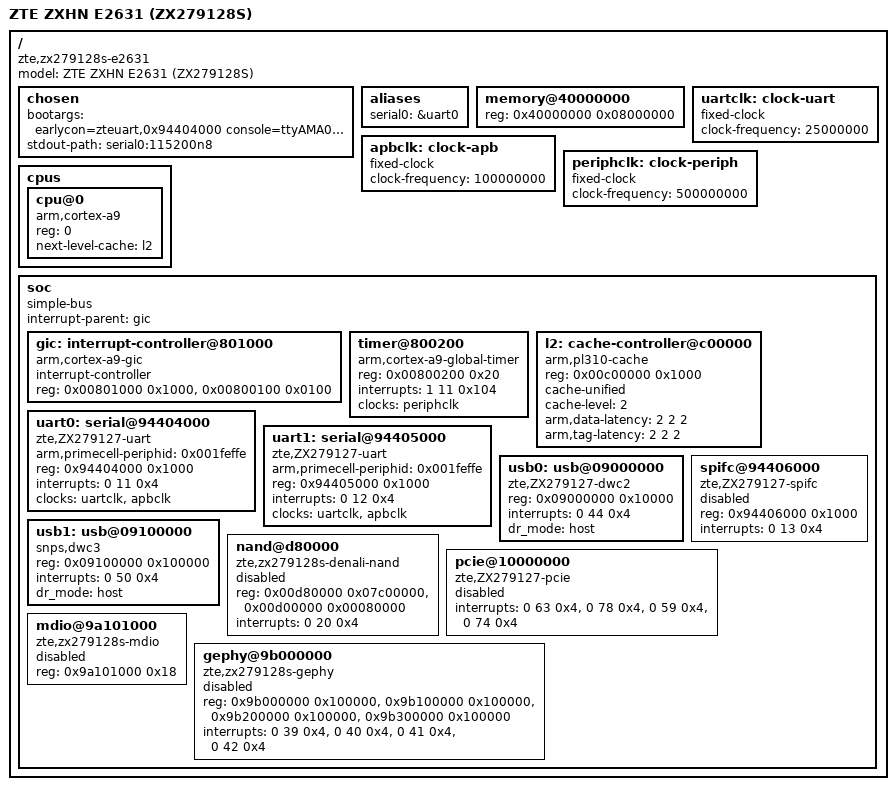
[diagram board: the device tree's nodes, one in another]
// SPDX-License-Identifier: GPL-2.0-only OR BSD-2-Clause
/*
 * ZTE ZXHN E2631 (ZX279128S, dual Cortex-A9) first-stage bring-up.
 *
 * Nodes verified against the vendor U-Boot device tree of firmware
 * ZXHN E2631 V1.0.0.6B5.8000.  Clock sources are fixed placeholders
 * until a ZX279128S clock controller driver exists.
 */

/dts-v1/;

/ {
	#address-cells = <1>;
	#size-cells = <1>;
	model = "ZTE ZXHN E2631 (ZX279128S)";
	compatible = "zte,zx279128s-e2631", "zte,zx279128-smp";

	chosen {
		bootargs = "earlycon=zteuart,0x94404000 console=ttyAMA0,115200n8 rdinit=/init loglevel=8";
		stdout-path = "serial0:115200n8";
	};

	aliases {
		serial0 = &uart0;
	};

	memory@40000000 {
		device_type = "memory";
		reg = <0x40000000 0x08000000>;
	};

	uartclk: clock-uart {
		compatible = "fixed-clock";
		#clock-cells = <0>;
		clock-frequency = <25000000>;
	};

	apbclk: clock-apb {
		compatible = "fixed-clock";
		#clock-cells = <0>;
		clock-frequency = <100000000>;
	};

	/* Placeholder: Cortex-A9 PERIPHCLK, to be calibrated on hardware. */
	periphclk: clock-periph {
		compatible = "fixed-clock";
		#clock-cells = <0>;
		clock-frequency = <500000000>;
	};

	cpus {
		#address-cells = <1>;
		#size-cells = <0>;

		/* Single core for first boot: the vendor secondary-core
		 * enable-method ("zte,zx279128-smp") is not ported yet. */
		cpu@0 {
			compatible = "arm,cortex-a9";
			device_type = "cpu";
			reg = <0>;
			next-level-cache = <&l2>;
		};
	};

	soc {
		#address-cells = <1>;
		#size-cells = <1>;
		compatible = "simple-bus";
		ranges;
		interrupt-parent = <&gic>;

		gic: interrupt-controller@801000 {
			compatible = "arm,cortex-a9-gic";
			#interrupt-cells = <3>;
			#address-cells = <1>;
			#size-cells = <1>;
			interrupt-controller;
			reg = <0x00801000 0x1000>,
			      <0x00800100 0x0100>;
		};

		timer@800200 {
			compatible = "arm,cortex-a9-global-timer";
			reg = <0x00800200 0x20>;
			interrupts = <1 11 0x104>;
			clocks = <&periphclk>;
		};

		l2: cache-controller@c00000 {
			compatible = "arm,pl310-cache";
			reg = <0x00c00000 0x1000>;
			cache-unified;
			cache-level = <2>;
			arm,data-latency = <2 2 2>;
			arm,tag-latency = <2 2 2>;
		};

		uart0: serial@94404000 {
			compatible = "zte,ZX279127-uart", "arm,pl011",
				     "arm,primecell";
			arm,primecell-periphid = <0x001feffe>;
			reg = <0x94404000 0x1000>;
			interrupts = <0 11 0x4>;
			clocks = <&uartclk>, <&apbclk>;
			clock-names = "uartclk", "apb_pclk";
			status = "okay";
		};

		uart1: serial@94405000 {
			compatible = "zte,ZX279127-uart", "arm,pl011",
				     "arm,primecell";
			arm,primecell-periphid = <0x001feffe>;
			reg = <0x94405000 0x1000>;
			interrupts = <0 12 0x4>;
			clocks = <&uartclk>, <&apbclk>;
			clock-names = "uartclk", "apb_pclk";
			status = "okay";
		};

		/* USB2 host, DesignWare HS OTG controller */
		usb0: usb@09000000 {
			compatible = "zte,ZX279127-dwc2", "snps,dwc2";
			reg = <0x09000000 0x10000>;
			interrupts = <0 44 0x4>;
			dr_mode = "host";
			status = "okay";
		};

		/* USB3 host, DesignWare DWC3 */
		usb1: usb@09100000 {
			compatible = "snps,dwc3";
			reg = <0x09100000 0x100000>;
			interrupts = <0 50 0x4>;
			dr_mode = "host";
			status = "okay";
		};

		/* Present but not ported yet; kept for documentation. */
		nand@d80000 {
			compatible = "zte,zx279128s-denali-nand";
			reg = <0x00d80000 0x07c00000>,
			      <0x00d00000 0x00080000>;
			interrupts = <0 20 0x4>;
			status = "disabled";
		};

		spifc@94406000 {
			compatible = "zte,ZX279127-spifc";
			reg = <0x94406000 0x1000>;
			interrupts = <0 13 0x4>;
			status = "disabled";
		};

		pcie@10000000 {
			compatible = "zte,ZX279127-pcie";
			interrupts = <0 63 0x4>, <0 78 0x4>,
				     <0 59 0x4>, <0 74 0x4>;
			status = "disabled";
		};

		mdio@9a101000 {
			compatible = "zte,zx279128s-mdio";
			reg = <0x9a101000 0x18>;
			status = "disabled";
		};

		gephy@9b000000 {
			compatible = "zte,zx279128s-gephy";
			reg = <0x9b000000 0x100000>,
			      <0x9b100000 0x100000>,
			      <0x9b200000 0x100000>,
			      <0x9b300000 0x100000>;
			interrupts = <0 39 0x4>, <0 40 0x4>,
				     <0 41 0x4>, <0 42 0x4>;
			status = "disabled";
		};
	};
};
